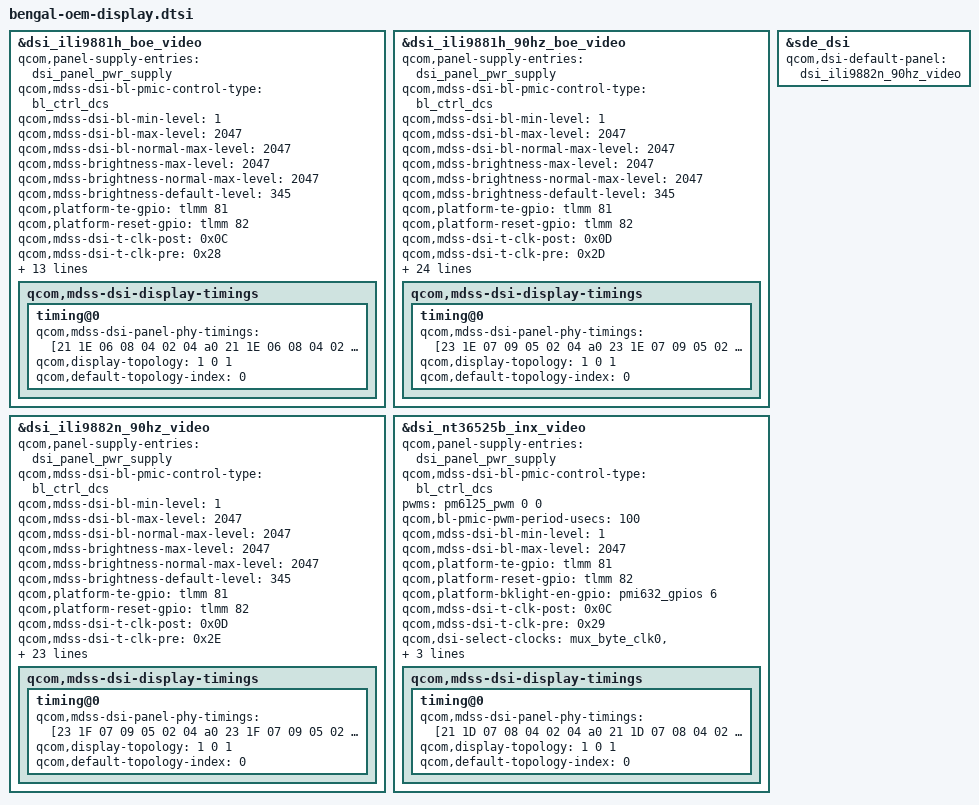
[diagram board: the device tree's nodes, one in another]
/* add for display modification */
#include "dsi-panel-ili9881h-boe-fhd-video.dtsi"
#include "dsi-panel-ili9881h-90hz-boe-fhd-video.dtsi"
#include "dsi-panel-ili9882n-90hz-fhd-video.dtsi"
#include "dsi-panel-nt36525b-inx-fhd-video.dtsi"

&dsi_ili9881h_boe_video {
	qcom,panel-supply-entries = <&dsi_panel_pwr_supply>;
	qcom,mdss-dsi-bl-pmic-control-type = "bl_ctrl_dcs";
	qcom,mdss-dsi-bl-min-level = <1>;
	qcom,mdss-dsi-bl-max-level = <2047>;
	qcom,mdss-dsi-bl-normal-max-level = <2047>;
	qcom,mdss-brightness-max-level = <2047>;
	qcom,mdss-brightness-normal-max-level = <2047>;
	qcom,mdss-brightness-default-level = <345>;
	qcom,platform-te-gpio = <&tlmm 81 0>;
	qcom,platform-reset-gpio = <&tlmm 82 0>;

	qcom,mdss-dsi-t-clk-post = <0x0C>;
	qcom,mdss-dsi-t-clk-pre = <0x28>;

	qcom,esd-check-enabled;
	qcom,mdss-dsi-panel-status-check-mode = "reg_read";
	qcom,mdss-dsi-panel-status-command = [06 01 00 01 00 00 01 0a];
	qcom,mdss-dsi-panel-status-command-state = "dsi_lp_mode";
	qcom,mdss-dsi-panel-status-value = <0x9c>;
	qcom,mdss-dsi-panel-status-read-length = <1>;

	qcom,dsi-select-clocks = "mux_byte_clk0", "mux_pixel_clk0",
				"src_byte_clk0", "src_pixel_clk0",
				"shadow_byte_clk0", "shadow_pixel_clk0";

	qcom,mdss-dsi-display-timings {
		timing@0{
			qcom,mdss-dsi-panel-phy-timings =
				[21 1E 06 08 04 02 04 a0
				21 1E 06 08 04 02 04 a0
				21 1E 06 08 04 02 04 a0
				21 1E 06 08 04 02 04 a0
				21 15 06 07 04 02 04 a0];

			qcom,display-topology = <1 0 1>;
			qcom,default-topology-index = <0>;
		};
	};
};

&dsi_ili9881h_90hz_boe_video {
	qcom,panel-supply-entries = <&dsi_panel_pwr_supply>;
	qcom,mdss-dsi-bl-pmic-control-type = "bl_ctrl_dcs";
	qcom,mdss-dsi-bl-min-level = <1>;
	qcom,mdss-dsi-bl-max-level = <2047>;
	qcom,mdss-dsi-bl-normal-max-level = <2047>;
	qcom,mdss-brightness-max-level = <2047>;
	qcom,mdss-brightness-normal-max-level = <2047>;
	qcom,mdss-brightness-default-level = <345>;
	qcom,platform-te-gpio = <&tlmm 81 0>;
	qcom,platform-reset-gpio = <&tlmm 82 0>;

	qcom,mdss-dsi-t-clk-post = <0x0D>;
	qcom,mdss-dsi-t-clk-pre = <0x2D>;

	qcom,dsi-supported-dfps-list = <90 60>;
	qcom,mdss-dsi-pan-enable-dynamic-fps;
	qcom,mdss-dsi-pan-fps-update =
		"dfps_immediate_porch_mode_vfp";
	qcom,mdss-dsi-min-refresh-rate = <60>;
	qcom,mdss-dsi-max-refresh-rate = <90>;
	oneplus,dfps-idle-off;

	qcom,esd-check-enabled;
	qcom,mdss-dsi-panel-status-check-mode = "reg_read";
	qcom,mdss-dsi-panel-status-command = [06 01 00 01 00 00 01 0a];
	qcom,mdss-dsi-panel-status-command-state = "dsi_lp_mode";
	qcom,mdss-dsi-panel-status-value = <0x9c>;
	qcom,mdss-dsi-panel-status-read-length = <1>;

	qcom,dsi-select-clocks = "mux_byte_clk0", "mux_pixel_clk0",
				"src_byte_clk0", "src_pixel_clk0",
				"shadow_byte_clk0", "shadow_pixel_clk0";

	qcom,dsi-dyn-clk-enable;
	qcom,dsi-dyn-clk-list =
		<835829280 832375440 828921600>;
	qcom,dsi-dyn-clk-type = "constant-fps-adjust-hfp";

	qcom,mdss-dsi-display-timings {
		timing@0{
                        qcom,mdss-dsi-panel-phy-timings =
                                [23 1E 07 09 05 02 04 a0
                                23 1E 07 09 05 02 04 a0
                                23 1E 07 09 05 02 04 a0
                                23 1E 07 09 05 02 04 a0
                                23 19 07 08 05 02 04 a0];

			qcom,display-topology = <1 0 1>;
			qcom,default-topology-index = <0>;
		};
	};
};

&dsi_ili9882n_90hz_video {
	qcom,panel-supply-entries = <&dsi_panel_pwr_supply>;
	qcom,mdss-dsi-bl-pmic-control-type = "bl_ctrl_dcs";
	qcom,mdss-dsi-bl-min-level = <1>;
	qcom,mdss-dsi-bl-max-level = <2047>;
	qcom,mdss-dsi-bl-normal-max-level = <2047>;
	qcom,mdss-brightness-max-level = <2047>;
	qcom,mdss-brightness-normal-max-level = <2047>;
	qcom,mdss-brightness-default-level = <345>;
	qcom,platform-te-gpio = <&tlmm 81 0>;
	qcom,platform-reset-gpio = <&tlmm 82 0>;

	qcom,mdss-dsi-t-clk-post = <0x0D>;
	qcom,mdss-dsi-t-clk-pre = <0x2E>;

	qcom,dsi-supported-dfps-list = <90 60>;
	qcom,mdss-dsi-pan-enable-dynamic-fps;
	qcom,mdss-dsi-pan-fps-update =
		"dfps_immediate_porch_mode_vfp";
	qcom,mdss-dsi-min-refresh-rate = <60>;
	qcom,mdss-dsi-max-refresh-rate = <90>;
	oneplus,dfps-idle-off;

	qcom,esd-check-enabled;
	qcom,mdss-dsi-panel-status-check-mode = "reg_read";
	qcom,mdss-dsi-panel-status-command = [06 01 00 01 00 00 01 0a];
	qcom,mdss-dsi-panel-status-command-state = "dsi_lp_mode";
	qcom,mdss-dsi-panel-status-value = <0x9c>;
	qcom,mdss-dsi-panel-status-read-length = <1>;

	qcom,dsi-select-clocks = "mux_byte_clk0", "mux_pixel_clk0",
				"src_byte_clk0", "src_pixel_clk0",
				"shadow_byte_clk0", "shadow_pixel_clk0";

	qcom,dsi-dyn-clk-enable;
	qcom,dsi-dyn-clk-list =
		<837688320 827217216>;
	qcom,dsi-dyn-clk-type = "constant-fps-adjust-hfp";

	qcom,mdss-dsi-display-timings {
		timing@0{
                        qcom,mdss-dsi-panel-phy-timings =
                                [23 1F 07 09 05 02 04 a0
                                23 1F 07 09 05 02 04 a0
                                23 1F 07 09 05 02 04 a0
                                23 1F 07 09 05 02 04 a0
                                23 1A 07 08 05 02 04 a0];

			qcom,display-topology = <1 0 1>;
			qcom,default-topology-index = <0>;
		};
	};
};

&dsi_nt36525b_inx_video {
	qcom,panel-supply-entries = <&dsi_panel_pwr_supply>;
	qcom,mdss-dsi-bl-pmic-control-type = "bl_ctrl_dcs";
	pwms = <&pm6125_pwm 0 0>;
	qcom,bl-pmic-pwm-period-usecs = <100>;
	qcom,mdss-dsi-bl-min-level = <1>;
	qcom,mdss-dsi-bl-max-level = <2047>;
	qcom,platform-te-gpio = <&tlmm 81 0>;
	qcom,platform-reset-gpio = <&tlmm 82 0>;
	qcom,platform-bklight-en-gpio = <&pmi632_gpios 6 0>;

	qcom,mdss-dsi-t-clk-post = <0x0C>;
	qcom,mdss-dsi-t-clk-pre = <0x29>;
	qcom,dsi-select-clocks = "mux_byte_clk0", "mux_pixel_clk0",
				"src_byte_clk0", "src_pixel_clk0",
				"shadow_byte_clk0", "shadow_pixel_clk0";

	qcom,mdss-dsi-display-timings {
		timing@0{
			qcom,mdss-dsi-panel-phy-timings =
				[21 1D 07 08 04 02 04 a0
				21 1D 07 08 04 02 04 a0
				21 1D 07 08 04 02 04 a0
				21 1D 07 08 04 02 04 a0
				21 16 06 07 04 02 04 a0];

			qcom,display-topology = <1 0 1>;
			qcom,default-topology-index = <0>;
		};
	};
};

&sde_dsi {
	qcom,dsi-default-panel = <&dsi_ili9882n_90hz_video>;
};
